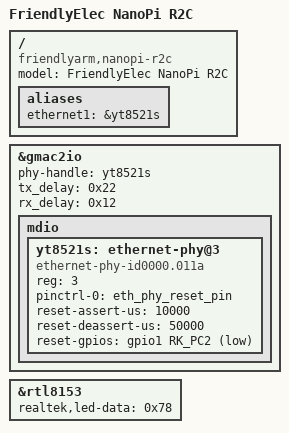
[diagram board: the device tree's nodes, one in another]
// SPDX-License-Identifier: (GPL-2.0+ OR MIT)
/*
 * Copyright (c) 2021 FriendlyElec Computer Tech. Co., Ltd.
 * (http://www.friendlyarm.com)
 *
 * Copyright (c) 2021 Tianling Shen <cnsztl@immortalwrt.org>
 */

/dts-v1/;

#include "rk3328-nanopi-r2s.dts"

/ {
	model = "FriendlyElec NanoPi R2C";
	compatible = "friendlyarm,nanopi-r2c", "rockchip,rk3328";

	aliases {
		ethernet1 = &yt8521s;
	};
};

&gmac2io {
	phy-handle = <&yt8521s>;
	tx_delay = <0x22>;
	rx_delay = <0x12>;

	mdio {
		/delete-node/ ethernet-phy@1;

		yt8521s: ethernet-phy@3 {
			compatible = "ethernet-phy-id0000.011a",
				     "ethernet-phy-ieee802.3-c22";
			reg = <3>;
			pinctrl-0 = <&eth_phy_reset_pin>;
			pinctrl-names = "default";
			reset-assert-us = <10000>;
			reset-deassert-us = <50000>;
			reset-gpios = <&gpio1 RK_PC2 GPIO_ACTIVE_LOW>;
		};
	};
};

&rtl8153 {
	realtek,led-data = <0x78>;
};
